VERSION ""

NS_ :

BS_:

BU_: FSM DCM BMS PDM INV DIM LOGGER DEBUG

BO_ 100 BMS_HEARTBEAT : 1 BMS
	SG_ HEARTBEAT : 0|1@1+ (1,0) [0|1] "" FSM,DCM,PDM,INV,DIM,DEBUG

BO_ 101 BMS_CAN_FIFO_OVERFLOW : 8 BMS
	SG_ TX_OVERFLOW_COUNT : 0|32@1+ (1,0) [0|4294967295] "" DEBUG
	SG_ RX_OVERFLOW_COUNT : 32|32@1+ (1,0) [0|4294967295] "" DEBUG

BO_ 102 BMS_STARTUP : 1 BMS
	SG_ STARTUP : 0|1@1+ (1,0) [0|1] "" DEBUG

BO_ 103 BMS_WATCHDOG_TIMEOUT : 1 BMS
	SG_ TASK_NAME : 0|2@1+ (1,0) [0|3] "" DEBUG

BO_ 104 BMS_NON_CRITICAL_ERRORS : 3 BMS
	SG_ STACK_WATERMARK_ABOVE_THRESHOLD_TASK1HZ : 0|1@1+ (1,0) [0|1] "" DEBUG
	SG_ STACK_WATERMARK_ABOVE_THRESHOLD_TASK1KHZ : 1|1@1+ (1,0) [0|1] "" DEBUG
	SG_ STACK_WATERMARK_ABOVE_THRESHOLD_TASKCANRX : 2|1@1+ (1,0) [0|1] "" DEBUG
	SG_ STACK_WATERMARK_ABOVE_THRESHOLD_TASKCANTX : 3|1@1+ (1,0) [0|1] "" DEBUG
	SG_ WATCHDOG_TIMEOUT : 4|1@1+ (1,0) [0|1] "" DEBUG
	SG_ SEGMENT_0_VOLTAGE_OUT_OF_RANGE : 5|1@1+ (1,0) [0|1] "" DEBUG
	SG_ SEGMENT_1_VOLTAGE_OUT_OF_RANGE : 6|1@1+ (1,0) [0|1] "" DEBUG
	SG_ SEGMENT_2_VOLTAGE_OUT_OF_RANGE : 7|1@1+ (1,0) [0|1] "" DEBUG
	SG_ SEGMENT_3_VOLTAGE_OUT_OF_RANGE : 8|1@1+ (1,0) [0|1] "" DEBUG
	SG_ SEGMENT_4_VOLTAGE_OUT_OF_RANGE : 9|1@1+ (1,0) [0|1] "" DEBUG
	SG_ SEGMENT_5_VOLTAGE_OUT_OF_RANGE : 10|1@1+ (1,0) [0|1] "" DEBUG
	SG_ PACK_VOLTAGE_OUT_OF_RANGE : 11|1@1+ (1,0) [0|1] "" DEBUG
	SG_ AVERAGE_CELL_VOLTAGE_OUT_OF_RANGE : 12|1@1+ (1,0) [0|1] "" DEBUG
	SG_ CELL_MONITOR_0_DIE_TEMP_OUT_OF_RANGE : 13|1@1+ (1,0) [0|1] "" DEBUG
	SG_ CELL_MONITOR_1_DIE_TEMP_OUT_OF_RANGE : 14|1@1+ (1,0) [0|1] "" DEBUG
	SG_ CELL_MONITOR_2_DIE_TEMP_OUT_OF_RANGE : 15|1@1+ (1,0) [0|1] "" DEBUG
	SG_ CELL_MONITOR_3_DIE_TEMP_OUT_OF_RANGE : 16|1@1+ (1,0) [0|1] "" DEBUG
	SG_ CELL_MONITOR_4_DIE_TEMP_OUT_OF_RANGE : 17|1@1+ (1,0) [0|1] "" DEBUG
	SG_ CELL_MONITOR_5_DIE_TEMP_OUT_OF_RANGE : 18|1@1+ (1,0) [0|1] "" DEBUG
	SG_ ITMP_CHARGER_HAS_OVERFLOW : 19|1@1+ (1,0) [0|1] "" DEBUG

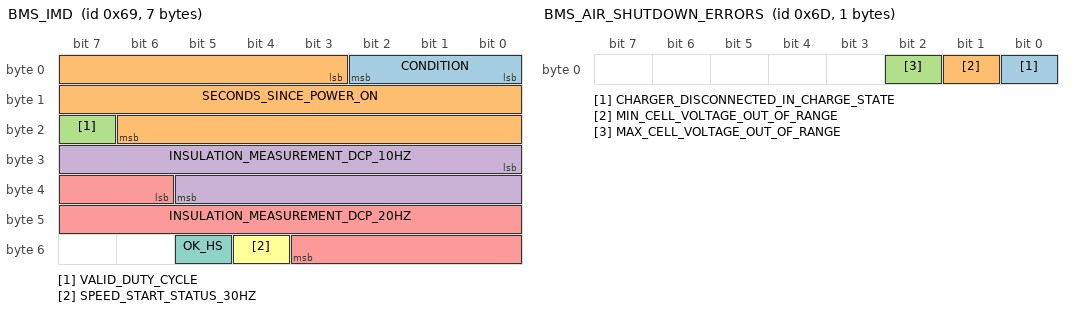
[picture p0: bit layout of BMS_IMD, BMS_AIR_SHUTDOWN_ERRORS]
BO_ 105 BMS_IMD : 7 BMS
	SG_ CONDITION : 0|3@1+ (1,0) [0|6] "" DEBUG
	SG_ SECONDS_SINCE_POWER_ON : 3|20@1+ (1,0) [0|604800] "seconds" DEBUG
	SG_ VALID_DUTY_CYCLE : 23|1@1+ (1,0) [0|1] "" DEBUG
	SG_ INSULATION_MEASUREMENT_DCP_10HZ : 24|14@1+ (1,0) [0|10000] "kOhms" DEBUG
	SG_ INSULATION_MEASUREMENT_DCP_20HZ : 38|14@1+ (1,0) [0|10000] "kOhms" DEBUG
	SG_ SPEED_START_STATUS_30HZ : 52|1@1+ (1,0) [0|1] "" DEBUG
	SG_ OK_HS : 53|1@1+ (1,0) [0|1] "" DIM,DEBUG

BO_ 106 BMS_IMD_PWM_OUTPUT : 4 BMS
	SG_ DUTY_CYCLE : 0|10@1+ (0.09775171065493646,0) [0|100] "%" DEBUG
	SG_ FREQUENCY : 10|19@1+ (0.0953676135399123,0) [0|50000] "Hz" DEBUG

BO_ 107 BMS_STATE_MACHINE : 1 BMS
	SG_ STATE : 0|3@1+ (1,0) [0|5] "" DEBUG

BO_ 108 BMS_STATE_OF_CHARGE : 2 BMS
	SG_ STATE_OF_CHARGE : 0|10@1+ (0.09775171065493646,0) [0|100] "%" DIM,DEBUG

BO_ 109 BMS_AIR_SHUTDOWN_ERRORS : 1 BMS
	SG_ CHARGER_DISCONNECTED_IN_CHARGE_STATE : 0|1@1+ (1,0) [0|1] "" DEBUG
	SG_ MIN_CELL_VOLTAGE_OUT_OF_RANGE : 1|1@1+ (1,0) [0|1] "" DEBUG
	SG_ MAX_CELL_VOLTAGE_OUT_OF_RANGE : 2|1@1+ (1,0) [0|1] "" DEBUG

BO_ 110 BMS_CHARGER : 1 BMS
	SG_ IS_CONNECTED : 0|1@1+ (1,0) [0|1] "" DEBUG

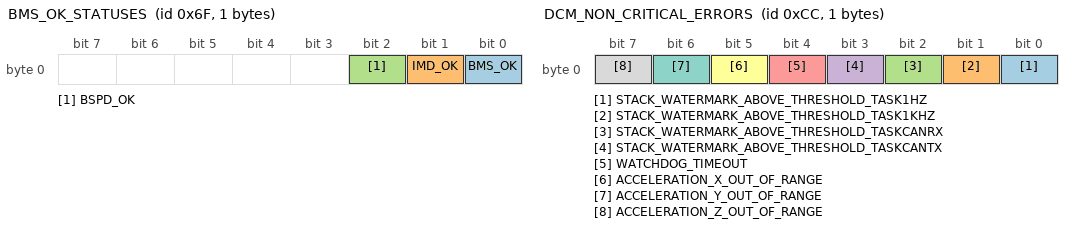
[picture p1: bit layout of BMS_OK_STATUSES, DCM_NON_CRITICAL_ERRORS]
BO_ 111 BMS_OK_STATUSES : 1 BMS
	SG_ BMS_OK : 0|1@1+ (1,0) [0|1] "" DEBUG
	SG_ IMD_OK : 1|1@1+ (1,0) [0|1] "" DEBUG
	SG_ BSPD_OK : 2|1@1+ (1,0) [0|1] "" DEBUG

BO_ 112 BMS_AIR_STATES : 1 BMS
	SG_ AIR_POSITIVE : 0|1@1+ (1,0) [0|1] "" FSM,DCM,PDM,DEBUG
	SG_ AIR_NEGATIVE : 1|1@1+ (1,0) [0|1] "" FSM,DCM,PDM,DEBUG

BO_ 113 BMS_MOTOR_SHUTDOWN_ERRORS : 1 BMS
	SG_ DUMMY_MOTOR_SHUTDOWN : 0|1@1+ (1,0) [0|1] "" DEBUG

BO_ 114 BMS_ACCUMULATOR_MIN_AND_MAX_VOLTAGES : 2 BMS
	SG_ MIN_CELL_VOLTAGE : 0|6@1+ (0.07936507936507936,0) [0|5] "V" DEBUG
	SG_ MAX_CELL_VOLTAGE : 6|6@1+ (0.07936507936507936,0) [0|5] "V" DEBUG

BO_ 115 BMS_ACCUMULATOR_PACK : 2 BMS
	SG_ PACK_VOLTAGE : 0|13@1+ (0.07935539006226346,0) [0|650] "V" DEBUG

BO_ 116 BMS_ACCUMULATOR_AVERAGE_CELL : 1 BMS
	SG_ AVERAGE_CELL_VOLTAGE : 0|6@1+ (0.07936507936507936,0) [0|5] "V" DEBUG

BO_ 117 BMS_ACCUMULATOR_SEGMENT_0 : 2 BMS
	SG_ SEGMENT_0_VOLTAGE : 0|11@1+ (0.07327796775769418,0) [0|150] "V" DEBUG

BO_ 118 BMS_ACCUMULATOR_SEGMENT_1 : 2 BMS
	SG_ SEGMENT_1_VOLTAGE : 0|11@1+ (0.07327796775769418,0) [0|150] "V" DEBUG

BO_ 119 BMS_ACCUMULATOR_SEGMENT_2 : 2 BMS
	SG_ SEGMENT_2_VOLTAGE : 0|11@1+ (0.07327796775769418,0) [0|150] "V" DEBUG

BO_ 120 BMS_ACCUMULATOR_SEGMENT_3 : 2 BMS
	SG_ SEGMENT_3_VOLTAGE : 0|11@1+ (0.07327796775769418,0) [0|150] "V" DEBUG

BO_ 121 BMS_ACCUMULATOR_SEGMENT_4 : 2 BMS
	SG_ SEGMENT_4_VOLTAGE : 0|11@1+ (0.07327796775769418,0) [0|150] "V" DEBUG

BO_ 122 BMS_ACCUMULATOR_SEGMENT_5 : 2 BMS
	SG_ SEGMENT_5_VOLTAGE : 0|11@1+ (0.07327796775769418,0) [0|150] "V" DEBUG

BO_ 123 BMS_CELL_MONITOR_0 : 2 BMS
	SG_ CELL_MONITOR_0_DIE_TEMPERATURE : 0|16@1- (0.004577776421399579,0) [-40|150] "degC" DEBUG

BO_ 124 BMS_CELL_MONITOR_1 : 1 BMS
	SG_ CELL_MONITOR_1_DIE_TEMPERATURE : 0|1@1- (1,0) [-40|150] "degC" DEBUG

BO_ 125 BMS_CELL_MONITOR_2 : 2 BMS
	SG_ CELL_MONITOR_2_DIE_TEMPERATURE : 0|9@1- (1,0) [-40|150] "degC" DEBUG

BO_ 126 BMS_CELL_MONITOR_3 : 2 BMS
	SG_ CELL_MONITOR_3_DIE_TEMPERATURE : 0|9@1- (1,0) [-40|150] "degC" DEBUG

BO_ 127 BMS_CELL_MONITOR_4 : 2 BMS
	SG_ CELL_MONITOR_4_DIE_TEMPERATURE : 0|9@1- (1,0) [-40|150] "degC" DEBUG

BO_ 128 BMS_CELL_MONITOR_5 : 2 BMS
	SG_ CELL_MONITOR_5_DIE_TEMPERATURE : 0|9@1- (1,0) [-40|150] "degC" DEBUG

BO_ 129 BMS_MAX_CELL_MONITOR : 2 BMS
	SG_ MAX_CELL_MONITOR_DIE_TEMPERATURE : 0|9@1- (1,0) [-40|150] "degC" DEBUG

BO_ 200 DCM_HEARTBEAT : 1 DCM
	SG_ HEARTBEAT : 0|1@1+ (1,0) [0|1] "" BMS,DEBUG

BO_ 201 DCM_CAN_FIFO_OVERFLOW : 8 DCM
	SG_ TX_OVERFLOW_COUNT : 0|32@1+ (1,0) [0|4294967295] "" DEBUG
	SG_ RX_OVERFLOW_COUNT : 32|32@1+ (1,0) [0|4294967295] "" DEBUG

BO_ 202 DCM_STARTUP : 1 DCM
	SG_ STARTUP : 0|1@1+ (1,0) [0|1] "" DEBUG

BO_ 203 DCM_WATCHDOG_TIMEOUT : 1 DCM
	SG_ TASK_NAME : 0|3@1+ (1,0) [0|5] "" DEBUG

BO_ 204 DCM_NON_CRITICAL_ERRORS : 1 DCM
	SG_ STACK_WATERMARK_ABOVE_THRESHOLD_TASK1HZ : 0|1@1+ (1,0) [0|1] "" DEBUG
	SG_ STACK_WATERMARK_ABOVE_THRESHOLD_TASK1KHZ : 1|1@1+ (1,0) [0|1] "" DEBUG
	SG_ STACK_WATERMARK_ABOVE_THRESHOLD_TASKCANRX : 2|1@1+ (1,0) [0|1] "" DEBUG
	SG_ STACK_WATERMARK_ABOVE_THRESHOLD_TASKCANTX : 3|1@1+ (1,0) [0|1] "" DEBUG
	SG_ WATCHDOG_TIMEOUT : 4|1@1+ (1,0) [0|1] "" DEBUG
	SG_ ACCELERATION_X_OUT_OF_RANGE : 5|1@1+ (1,0) [0|1] "" DEBUG
	SG_ ACCELERATION_Y_OUT_OF_RANGE : 6|1@1+ (1,0) [0|1] "" DEBUG
	SG_ ACCELERATION_Z_OUT_OF_RANGE : 7|1@1+ (1,0) [0|1] "" DEBUG

BO_ 205 DCM_STATE_MACHINE : 1 DCM
	SG_ STATE : 0|2@1+ (1,0) [0|2] "" DEBUG

BO_ 206 DCM_TORQUE_REQUEST_FRONT : 8 DCM
	SG_ FR_TORQUE_REQUEST : 0|32@1- (1,0) [-90|90] "Nm" INV,LOGGER,DEBUG
	SG_ FL_TORQUE_REQUEST : 32|32@1- (1,0) [-90|90] "Nm" INV,LOGGER,DEBUG

BO_ 207 DCM_TORQUE_REQUEST_REAR : 8 DCM
	SG_ RR_TORQUE_REQUEST : 0|32@1- (1,0) [-90|90] "Nm" INV,LOGGER,DEBUG
	SG_ RL_TORQUE_REQUEST : 32|32@1- (1,0) [-90|90] "Nm" INV,LOGGER,DEBUG

BO_ 208 DCM_AIR_SHUTDOWN_ERRORS : 1 DCM
	SG_ DUMMY_AIR_SHUTDOWN : 0|1@1+ (1,0) [0|1] "" DEBUG

BO_ 209 DCM_MOTOR_SHUTDOWN_ERRORS : 1 DCM
	SG_ DUMMY_MOTOR_SHUTDOWN : 0|1@1+ (1,0) [0|1] "" DEBUG

BO_ 210 DCM_ACCELERATION_X : 2 DCM
	SG_ ACCELERATION_X : 0|10@1+ (0.09775171065493646,0) [0|100] "m/s^2" DEBUG

BO_ 211 DCM_ACCELERATION_Y : 2 DCM
	SG_ ACCELERATION_Y : 0|10@1+ (0.09775171065493646,0) [0|100] "m/s^2" DEBUG

BO_ 212 DCM_ACCELERATION_Z : 2 DCM
	SG_ ACCELERATION_Z : 0|10@1+ (0.09775171065493646,0) [0|100] "m/s^2" DEBUG

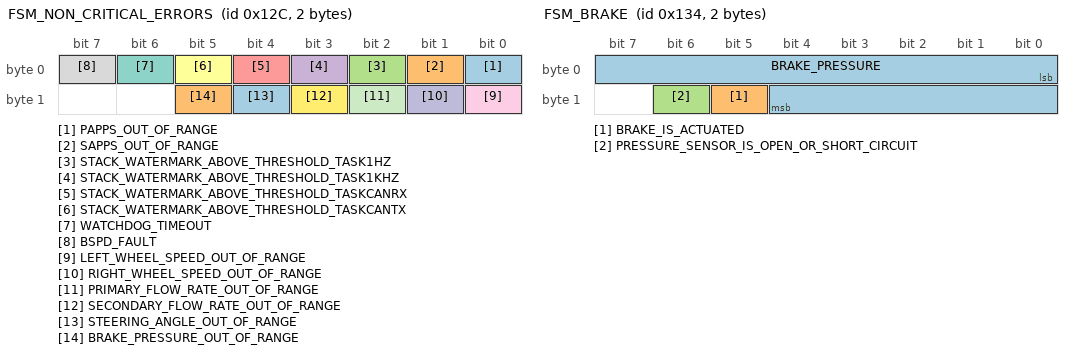
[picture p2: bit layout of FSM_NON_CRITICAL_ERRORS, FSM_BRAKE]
BO_ 300 FSM_NON_CRITICAL_ERRORS : 2 FSM
	SG_ PAPPS_OUT_OF_RANGE : 0|1@1+ (1,0) [0|1] "" DEBUG
	SG_ SAPPS_OUT_OF_RANGE : 1|1@1+ (1,0) [0|1] "" DEBUG
	SG_ STACK_WATERMARK_ABOVE_THRESHOLD_TASK1HZ : 2|1@1+ (1,0) [0|1] "" DEBUG
	SG_ STACK_WATERMARK_ABOVE_THRESHOLD_TASK1KHZ : 3|1@1+ (1,0) [0|1] "" DEBUG
	SG_ STACK_WATERMARK_ABOVE_THRESHOLD_TASKCANRX : 4|1@1+ (1,0) [0|1] "" DEBUG
	SG_ STACK_WATERMARK_ABOVE_THRESHOLD_TASKCANTX : 5|1@1+ (1,0) [0|1] "" DEBUG
	SG_ WATCHDOG_TIMEOUT : 6|1@1+ (1,0) [0|1] "" DEBUG
	SG_ BSPD_FAULT : 7|1@1+ (1,0) [0|1] "" DIM,DEBUG
	SG_ LEFT_WHEEL_SPEED_OUT_OF_RANGE : 8|1@1+ (1,0) [0|1] "" DEBUG
	SG_ RIGHT_WHEEL_SPEED_OUT_OF_RANGE : 9|1@1+ (1,0) [0|1] "" DEBUG
	SG_ PRIMARY_FLOW_RATE_OUT_OF_RANGE : 10|1@1+ (1,0) [0|1] "" DEBUG
	SG_ SECONDARY_FLOW_RATE_OUT_OF_RANGE : 11|1@1+ (1,0) [0|1] "" DEBUG
	SG_ STEERING_ANGLE_OUT_OF_RANGE : 12|1@1+ (1,0) [0|1] "" DEBUG
	SG_ BRAKE_PRESSURE_OUT_OF_RANGE : 13|1@1+ (1,0) [0|1] "" DEBUG

BO_ 301 FSM_HEARTBEAT : 1 FSM
	SG_ HEARTBEAT : 0|1@1+ (1,0) [0|1] "" BMS,DEBUG

BO_ 302 FSM_CAN_FIFO_OVERFLOW : 8 FSM
	SG_ TX_OVERFLOW_COUNT : 0|32@1+ (1,0) [0|4294967295] "" DEBUG
	SG_ RX_OVERFLOW_COUNT : 32|32@1+ (1,0) [0|4294967295] "" DEBUG

BO_ 303 FSM_STARTUP : 1 FSM
	SG_ STARTUP : 0|1@1+ (1,0) [0|1] "" DEBUG

BO_ 304 FSM_WATCHDOG_TIMEOUT : 1 FSM
	SG_ TASK_NAME : 0|3@1+ (1,0) [0|5] "" DEBUG

BO_ 305 FSM_STATE_MACHINE : 1 FSM
	SG_ STATE : 0|1@1+ (1,0) [0|1] "" DEBUG

BO_ 306 FSM_AIR_SHUTDOWN : 1 FSM
	SG_ AIR_SHUTDOWN : 0|1@1+ (1,0) [0|1] "" DEBUG

BO_ 307 FSM_FLOW_METER : 3 FSM
	SG_ PRIMARY_FLOW_RATE : 0|9@1+ (0.04892367906066536,0) [0|25] "L/min" DEBUG
	SG_ SECONDARY_FLOW_RATE : 9|9@1+ (0.04892367906066536,0) [0|25] "L/min" DEBUG

BO_ 308 FSM_BRAKE : 2 FSM
	SG_ BRAKE_PRESSURE : 0|13@1+ (0.06104260774020266,0) [0|500] "psi" DEBUG
	SG_ BRAKE_IS_ACTUATED : 13|1@1+ (1,0) [0|1] "" DCM,DEBUG
	SG_ PRESSURE_SENSOR_IS_OPEN_OR_SHORT_CIRCUIT : 14|1@1+ (1,0) [0|1] "" DEBUG

BO_ 309 FSM_WHEEL_SPEED_SENSOR : 3 FSM
	SG_ LEFT_WHEEL_SPEED : 0|10@1+ (0.09775171065493646,0) [0|100] "km/h" DCM,DEBUG
	SG_ RIGHT_WHEEL_SPEED : 10|10@1+ (0.09775171065493646,0) [0|100] "km/h" DCM,DEBUG

BO_ 310 FSM_AIR_SHUTDOWN_ERRORS : 1 FSM
	SG_ DUMMY_AIR_SHUTDOWN : 0|1@1+ (1,0) [0|1] "" DEBUG

BO_ 311 FSM_STEERING_ANGLE_SENSOR : 2 FSM
	SG_ STEERING_ANGLE : 0|13@1- (0.04395604395604396,0) [-180|180] "degrees" DCM,DEBUG

BO_ 312 FSM_PRIMARY_APPS : 2 FSM
	SG_ PAPPS_MAPPED_PEDAL_PERCENTAGE : 0|10@1+ (0.09775171065493646,0) [0|100] "%" DEBUG

BO_ 313 FSM_SECONDARY_APPS : 2 FSM
	SG_ SAPPS_MAPPED_PEDAL_PERCENTAGE : 0|10@1+ (0.09775171065493646,0) [0|100] "%" DEBUG

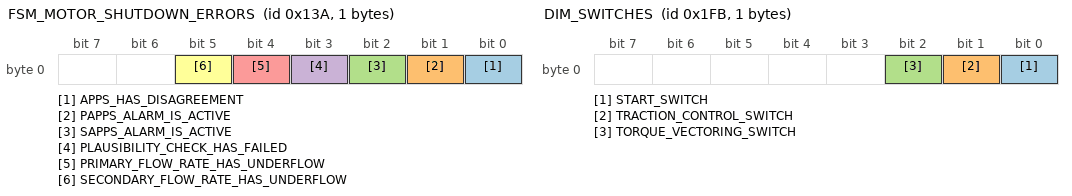
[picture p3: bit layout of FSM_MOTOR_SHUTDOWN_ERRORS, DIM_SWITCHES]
BO_ 314 FSM_MOTOR_SHUTDOWN_ERRORS : 1 FSM
	SG_ APPS_HAS_DISAGREEMENT : 0|1@1+ (1,0) [0|1] "" DEBUG
	SG_ PAPPS_ALARM_IS_ACTIVE : 1|1@1+ (1,0) [0|1] "" DEBUG
	SG_ SAPPS_ALARM_IS_ACTIVE : 2|1@1+ (1,0) [0|1] "" DEBUG
	SG_ PLAUSIBILITY_CHECK_HAS_FAILED : 3|1@1+ (1,0) [0|1] "" DEBUG
	SG_ PRIMARY_FLOW_RATE_HAS_UNDERFLOW : 4|1@1+ (1,0) [0|1] "" DEBUG
	SG_ SECONDARY_FLOW_RATE_HAS_UNDERFLOW : 5|1@1+ (1,0) [0|1] "" DEBUG

BO_ 315 FSM_PEDAL_POSITION : 2 FSM
	SG_ MAPPED_PEDAL_PERCENTAGE : 0|10@1+ (0.09775171065493646,0) [0|100] "%" DCM,DEBUG

BO_ 400 PDM_NON_CRITICAL_ERRORS : 3 PDM
	SG_ MISSING_HEARTBEAT : 0|1@1+ (1,0) [0|1] "" DEBUG
	SG_ BOOST_PGOOD_FAULT : 1|1@1+ (1,0) [0|1] "" DEBUG
	SG_ CHARGER_FAULT : 2|1@1+ (1,0) [0|1] "" DEBUG
	SG_ EFUSE_FAULT : 3|1@1+ (1,0) [0|1] "" DEBUG
	SG_ STACK_WATERMARK_ABOVE_THRESHOLD_TASK1HZ : 4|1@1+ (1,0) [0|1] "" DEBUG
	SG_ STACK_WATERMARK_ABOVE_THRESHOLD_TASK1KHZ : 5|1@1+ (1,0) [0|1] "" DEBUG
	SG_ STACK_WATERMARK_ABOVE_THRESHOLD_TASKCANRX : 6|1@1+ (1,0) [0|1] "" DEBUG
	SG_ STACK_WATERMARK_ABOVE_THRESHOLD_TASKCANTX : 7|1@1+ (1,0) [0|1] "" DEBUG
	SG_ WATCHDOG_TIMEOUT : 8|1@1+ (1,0) [0|1] "" DEBUG
	SG_ VBAT_VOLTAGE_OUT_OF_RANGE : 9|1@1+ (1,0) [0|1] "" DEBUG
	SG_ _24V_AUX_VOLTAGE_OUT_OF_RANGE : 10|1@1+ (1,0) [0|1] "" DEBUG
	SG_ _24V_ACC_VOLTAGE_OUT_OF_RANGE : 11|1@1+ (1,0) [0|1] "" DEBUG
	SG_ AUX1_CURRENT_OUT_OF_RANGE : 12|1@1+ (1,0) [0|1] "" DEBUG
	SG_ AUX2_CURRENT_OUT_OF_RANGE : 13|1@1+ (1,0) [0|1] "" DEBUG
	SG_ LEFT_INVERTER_CURRENT_OUT_OF_RANGE : 14|1@1+ (1,0) [0|1] "" DEBUG
	SG_ RIGHT_INVERTER_CURRENT_OUT_OF_RANGE : 15|1@1+ (1,0) [0|1] "" DEBUG
	SG_ ENERGY_METER_CURRENT_OUT_OF_RANGE : 16|1@1+ (1,0) [0|1] "" DEBUG
	SG_ CAN_CURRENT_OUT_OF_RANGE : 17|1@1+ (1,0) [0|1] "" DEBUG
	SG_ AIR_SHUTDOWN_CURRENT_OUT_OF_RANGE : 18|1@1+ (1,0) [0|1] "" DEBUG

BO_ 401 PDM_HEARTBEAT : 1 PDM
	SG_ HEARTBEAT : 0|1@1+ (1,0) [0|1] "" BMS,DEBUG

BO_ 402 PDM_CAN_FIFO_OVERFLOW : 8 PDM
	SG_ TX_OVERFLOW_COUNT : 0|32@1+ (1,0) [0|4294967295] "" DEBUG
	SG_ RX_OVERFLOW_COUNT : 32|32@1+ (1,0) [0|4294967295] "" DEBUG

BO_ 403 PDM_STARTUP : 1 PDM
	SG_ STARTUP : 0|1@1+ (1,0) [0|1] "" DEBUG

BO_ 404 PDM_AIR_SHUTDOWN_ERRORS : 1 PDM
	SG_ DUMMY_AIR_SHUTDOWN : 0|1@1+ (1,0) [0|1] "" DEBUG

BO_ 405 PDM_MOTOR_SHUTDOWN_ERRORS : 1 PDM
	SG_ DUMMY_MOTOR_SHUTDOWN : 0|1@1+ (1,0) [0|1] "" DEBUG

BO_ 406 PDM_AUX1_AUX2_CURRENT : 4 PDM
	SG_ AUXILIARY1_CURRENT : 0|16@1+ (0.07629510948348212,0) [0|5000] "mA" DEBUG
	SG_ AUXILIARY2_CURRENT : 16|16@1+ (0.07629510948348212,0) [0|5000] "mA" DEBUG

BO_ 407 PDM_ENERGY_METER_CURRENT : 4 PDM
	SG_ ENERGY_METER_CURRENT : 0|16@1+ (0.07629510948348212,0) [0|5000] "mA" DEBUG
	SG_ UNUSED : 16|16@1+ (0.07629510948348212,0) [0|5000] "mA" DEBUG

BO_ 408 PDM_AIRSHDN_CANGLV_CURRENT : 4 PDM
	SG_ CAN_CURRENT : 0|16@1+ (0.07629510948348212,0) [0|5000] "mA" DEBUG
	SG_ AIR_SHUTDOWN_CURRENT : 16|16@1+ (0.1,0) [0|5000] "mA" DEBUG

BO_ 409 PDM_INVERTER_CURRENT : 4 PDM
	SG_ LEFT_INVERTER_CURRENT : 0|16@1+ (0.1,0) [0|5000] "mA" DEBUG
	SG_ RIGHT_INVERTER_CURRENT : 16|16@1+ (0.1,0) [0|5000] "mA" DEBUG

BO_ 410 PDM_24V : 3 PDM
	SG_ _24V_AUX : 0|9@1+ (0.1,0) [0|30] "V" DEBUG
	SG_ _24V_ACC : 9|9@1+ (0.1,0) [0|30] "V" DEBUG

BO_ 411 PDM_VBAT : 1 PDM
	SG_ VBAT : 0|7@1+ (0.1,0) [0|10] "V" DEBUG

BO_ 412 PDM_WATCHDOG_TIMEOUT : 1 PDM
	SG_ TASK_NAME : 0|3@1+ (1,0) [0|5] "" DEBUG

BO_ 413 PDM_STATE_MACHINE : 1 PDM
	SG_ STATE : 0|2@1+ (1,0) [0|2] "" DEBUG

BO_ 500 DIM_HEARTBEAT : 1 DIM
	SG_ HEARTBEAT : 0|1@1+ (1,0) [0|1] "" FSM,DCM,BMS,PDM,DEBUG

BO_ 501 DIM_CAN_FIFO_OVERFLOW : 8 DIM
	SG_ TX_OVERFLOW_COUNT : 0|32@1+ (1,0) [0|4294967295] "" DEBUG
	SG_ RX_OVERFLOW_COUNT : 32|32@1+ (1,0) [0|4294967295] "" DEBUG

BO_ 502 DIM_STARTUP : 1 DIM
	SG_ STARTUP : 0|1@1+ (1,0) [0|1] "" DEBUG

BO_ 503 DIM_STATE_MACHINE : 1 DIM
	SG_ STATE : 0|1@1+ (1,0) [0|1] "" DEBUG

BO_ 504 DIM_WATCHDOG_TIMEOUT : 1 DIM
	SG_ TASK_NAME : 0|3@1+ (1,0) [0|5] "" DEBUG

BO_ 505 DIM_REGEN_PADDLE : 2 DIM
	SG_ RAW_PADDLE_POSITION : 0|6@1+ (0.1,0) [0|3.5] "V" DEBUG
	SG_ MAPPED_PADDLE_POSITION : 6|10@1+ (0.1,0) [0|100] "%" DCM,DEBUG

BO_ 506 DIM_DRIVE_MODE_SWITCH : 1 DIM
	SG_ DRIVE_MODE : 0|3@1+ (1,0) [0|5] "" DCM,DEBUG

BO_ 507 DIM_SWITCHES : 1 DIM
	SG_ START_SWITCH : 0|1@1+ (1,0) [0|1] "" DCM,DEBUG
	SG_ TRACTION_CONTROL_SWITCH : 1|1@1+ (1,0) [0|1] "" DCM,DEBUG
	SG_ TORQUE_VECTORING_SWITCH : 2|1@1+ (1,0) [0|1] "" DCM,DEBUG

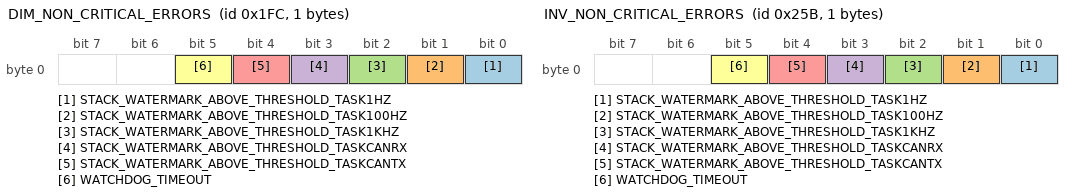
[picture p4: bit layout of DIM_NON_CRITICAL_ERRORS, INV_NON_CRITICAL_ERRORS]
BO_ 508 DIM_NON_CRITICAL_ERRORS : 1 DIM
	SG_ STACK_WATERMARK_ABOVE_THRESHOLD_TASK1HZ : 0|1@1+ (1,0) [0|1] "" DEBUG
	SG_ STACK_WATERMARK_ABOVE_THRESHOLD_TASK100HZ : 1|1@1+ (1,0) [0|1] "" DEBUG
	SG_ STACK_WATERMARK_ABOVE_THRESHOLD_TASK1KHZ : 2|1@1+ (1,0) [0|1] "" DEBUG
	SG_ STACK_WATERMARK_ABOVE_THRESHOLD_TASKCANRX : 3|1@1+ (1,0) [0|1] "" DEBUG
	SG_ STACK_WATERMARK_ABOVE_THRESHOLD_TASKCANTX : 4|1@1+ (1,0) [0|1] "" DEBUG
	SG_ WATCHDOG_TIMEOUT : 5|1@1+ (1,0) [0|1] "" DEBUG

BO_ 509 DIM_AIR_SHUTDOWN_ERRORS : 1 DIM
	SG_ DUMMY_AIR_SHUTDOWN : 0|1@1+ (1,0) [0|1] "" DEBUG

BO_ 510 DIM_MOTOR_SHUTDOWN_ERRORS : 1 DIM
	SG_ DUMMY_MOTOR_SHUTDOWN : 0|1@1+ (1,0) [0|1] "" DEBUG

BO_ 600 INV_HEARTBEAT : 1 INV
	SG_ HEARTBEAT : 0|1@1+ (1,0) [0|1] "" FSM,DCM,BMS,PDM,DIM,DEBUG

BO_ 601 INV_CAN_FIFO_OVERFLOW : 8 INV
	SG_ TX_OVERFLOW_COUNT : 0|32@1+ (1,0) [0|4294967295] "" DEBUG
	SG_ RX_OVERFLOW_COUNT : 32|32@1+ (1,0) [0|4294967295] "" DEBUG

BO_ 602 INV_WATCHDOG_TIMEOUT : 1 INV
	SG_ TASK_NAME : 0|3@1+ (1,0) [0|5] "" DEBUG

BO_ 603 INV_NON_CRITICAL_ERRORS : 1 INV
	SG_ STACK_WATERMARK_ABOVE_THRESHOLD_TASK1HZ : 0|1@1+ (1,0) [0|1] "" LOGGER,DEBUG
	SG_ STACK_WATERMARK_ABOVE_THRESHOLD_TASK100HZ : 1|1@1+ (1,0) [0|1] "" LOGGER,DEBUG
	SG_ STACK_WATERMARK_ABOVE_THRESHOLD_TASK1KHZ : 2|1@1+ (1,0) [0|1] "" LOGGER,DEBUG
	SG_ STACK_WATERMARK_ABOVE_THRESHOLD_TASKCANRX : 3|1@1+ (1,0) [0|1] "" LOGGER,DEBUG
	SG_ STACK_WATERMARK_ABOVE_THRESHOLD_TASKCANTX : 4|1@1+ (1,0) [0|1] "" LOGGER,DEBUG
	SG_ WATCHDOG_TIMEOUT : 5|1@1+ (1,0) [0|1] "" LOGGER,DEBUG

BO_ 604 INV_AIR_SHUTDOWN_ERRORS : 1 INV
	SG_ DUMMY_AIR_SHUTDOWN : 0|1@1+ (1,0) [0|1] "" DEBUG

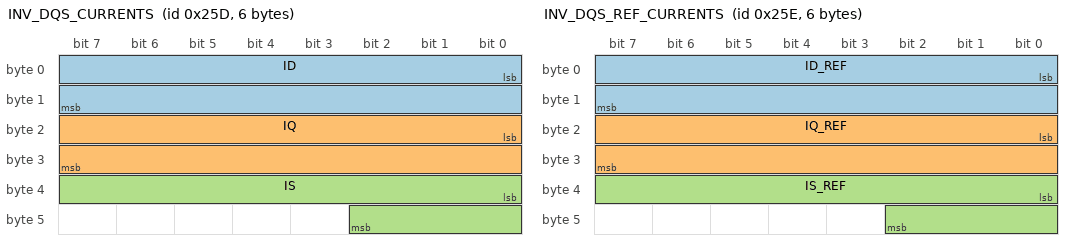
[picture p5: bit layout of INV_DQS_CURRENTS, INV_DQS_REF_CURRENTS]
BO_ 605 INV_DQS_CURRENTS : 6 INV
	SG_ ID : 0|16@1- (0.1,0) [-3276.8|3276.7] "A" DEBUG
	SG_ IQ : 16|16@1- (0.1,0) [-3276.8|3276.7] "A" DEBUG
	SG_ IS : 32|11@1+ (0.1,0) [0|200] "A" DEBUG

BO_ 606 INV_DQS_REF_CURRENTS : 6 INV
	SG_ ID_REF : 0|16@1- (0.1,0) [-3276.8|3276.7] "A" DEBUG
	SG_ IQ_REF : 16|16@1- (0.1,0) [-3276.8|3276.7] "A" DEBUG
	SG_ IS_REF : 32|11@1+ (0.1,0) [0|200] "A" DEBUG

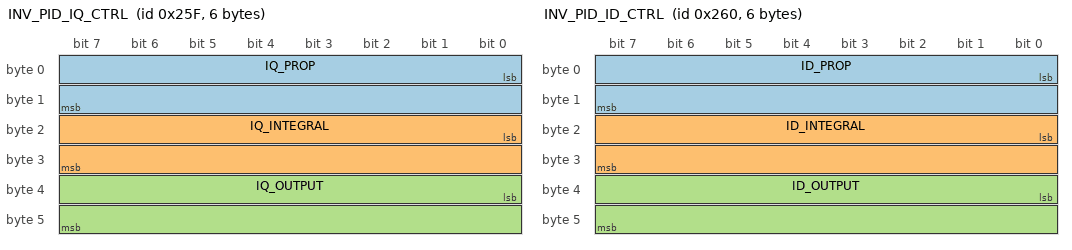
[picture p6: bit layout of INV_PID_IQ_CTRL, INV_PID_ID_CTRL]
BO_ 607 INV_PID_IQ_CTRL : 6 INV
	SG_ IQ_PROP : 0|16@1- (0.1,0) [-3276.8|3276.7] "V" DEBUG
	SG_ IQ_INTEGRAL : 16|16@1- (0.1,0) [-3276.8|3276.7] "V" DEBUG
	SG_ IQ_OUTPUT : 32|16@1- (0.1,0) [-3276.8|3276.7] "V" DEBUG

BO_ 608 INV_PID_ID_CTRL : 6 INV
	SG_ ID_PROP : 0|16@1- (0.1,0) [-3276.8|3276.7] "V" DEBUG
	SG_ ID_INTEGRAL : 16|16@1- (0.1,0) [-3276.8|3276.7] "V" DEBUG
	SG_ ID_OUTPUT : 32|16@1- (0.1,0) [-3276.8|3276.7] "V" DEBUG

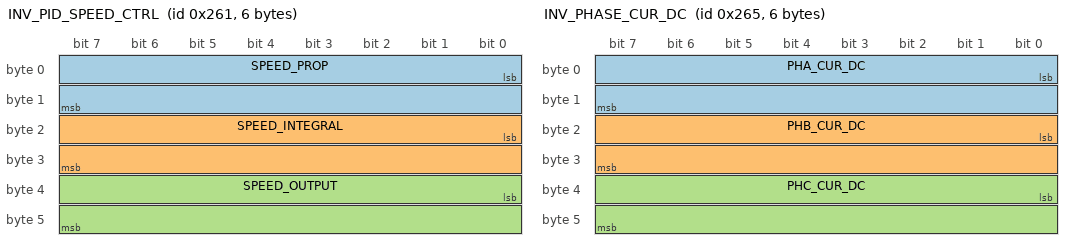
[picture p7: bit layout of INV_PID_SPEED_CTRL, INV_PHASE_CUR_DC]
BO_ 609 INV_PID_SPEED_CTRL : 6 INV
	SG_ SPEED_PROP : 0|16@1- (0.1,0) [-3276.8|3276.7] "Nm" DEBUG
	SG_ SPEED_INTEGRAL : 16|16@1- (0.1,0) [-3276.8|3276.7] "Nm" DEBUG
	SG_ SPEED_OUTPUT : 32|16@1- (0.1,0) [-3276.8|3276.7] "Nm" DEBUG

BO_ 610 INV_VPHASE_LN : 2 INV
	SG_ VPHASE_LN : 0|13@1+ (0.1,0) [0|500] "V" DEBUG

BO_ 611 INV_MOD_INDEX : 2 INV
	SG_ MOD_INDEX : 0|10@1+ (0.1,0) [0|100] "%" DEBUG

BO_ 612 INV_BUS_VOLTAGE : 2 INV
	SG_ BUS_VOLTAGE : 0|13@1+ (0.1,0) [0|800] "V" DEBUG

BO_ 613 INV_PHASE_CUR_DC : 6 INV
	SG_ PHA_CUR_DC : 0|16@1- (0.09999999999999999,0) [-3276.8|3276.7] "A" DEBUG
	SG_ PHB_CUR_DC : 16|16@1- (0.09999999999999999,0) [-3276.8|3276.7] "A" DEBUG
	SG_ PHC_CUR_DC : 32|16@1- (0.09999999999999999,0) [-3276.8|3276.7] "A" DEBUG

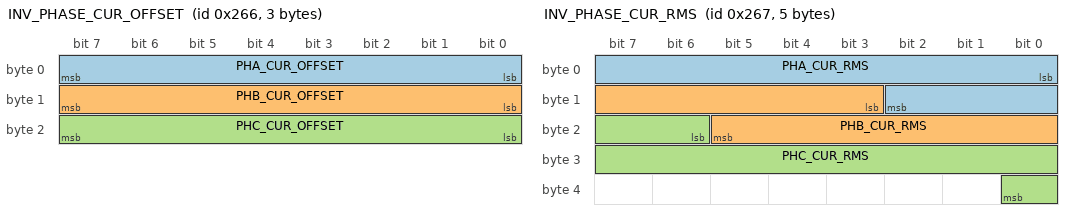
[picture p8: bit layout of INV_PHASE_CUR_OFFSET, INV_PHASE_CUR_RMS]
BO_ 614 INV_PHASE_CUR_OFFSET : 3 INV
	SG_ PHA_CUR_OFFSET : 0|8@1- (1,0) [-128|127] "A" DEBUG
	SG_ PHB_CUR_OFFSET : 8|8@1- (1,0) [-128|127] "A" DEBUG
	SG_ PHC_CUR_OFFSET : 16|8@1- (1,0) [-128|127] "A" DEBUG

BO_ 615 INV_PHASE_CUR_RMS : 5 INV
	SG_ PHA_CUR_RMS : 0|11@1+ (0.1,0) [0|200] "Arms" DEBUG
	SG_ PHB_CUR_RMS : 11|11@1+ (0.1,0) [0|200] "Arms" DEBUG
	SG_ PHC_CUR_RMS : 22|11@1+ (0.1,0) [0|200] "Arms" DEBUG

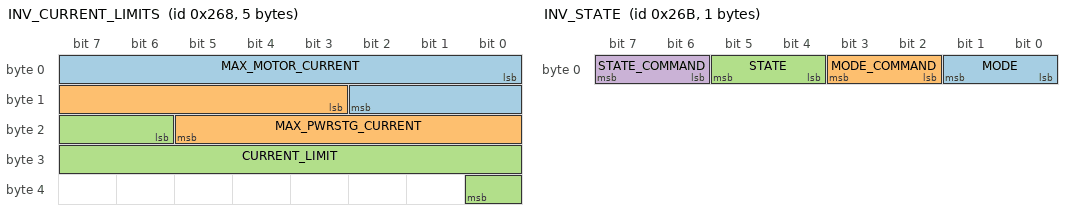
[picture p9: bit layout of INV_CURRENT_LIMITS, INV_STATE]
BO_ 616 INV_CURRENT_LIMITS : 5 INV
	SG_ MAX_MOTOR_CURRENT : 0|11@1+ (0.1,0) [0|150] "A" DEBUG
	SG_ MAX_PWRSTG_CURRENT : 11|11@1+ (0.1,0) [0|150] "A" DEBUG
	SG_ CURRENT_LIMIT : 22|11@1+ (0.1,0) [0|150] "A" DEBUG

BO_ 617 INV_TEMPS : 4 INV
	SG_ PWRSTG_TEMP : 0|16@1- (0.1,0) [-3276.8|3276.7] "degC" DEBUG
	SG_ MOTOR_TEMP : 16|16@1- (0.1,0) [-3276.8|3276.7] "degC" DEBUG

BO_ 618 INV_ROTOR : 4 INV
	SG_ ROTOR_POSITION : 0|12@1+ (0.1,0) [0|400] "degrees" DEBUG
	SG_ ROTOR_SPEED : 12|16@1- (1,0) [-32768|32767] "rpm" DEBUG

BO_ 619 INV_STATE : 1 INV
	SG_ MODE : 0|2@1+ (1,0) [0|3] "" DEBUG
	SG_ MODE_COMMAND : 2|2@1+ (1,0) [0|3] "" DEBUG
	SG_ STATE : 4|2@1+ (1,0) [0|3] "" DEBUG
	SG_ STATE_COMMAND : 6|2@1+ (1,0) [0|3] "" DEBUG

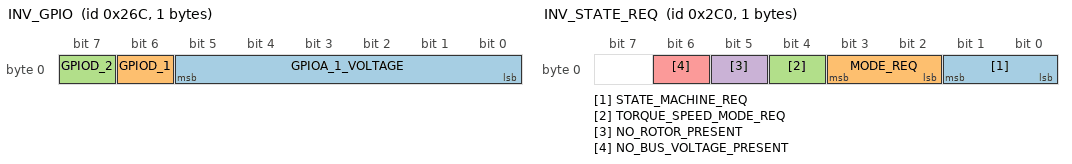
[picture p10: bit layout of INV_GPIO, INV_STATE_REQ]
BO_ 620 INV_GPIO : 1 INV
	SG_ GPIOA_1_VOLTAGE : 0|6@1+ (0.1,0) [0|3.5] "V" DEBUG
	SG_ GPIOD_1 : 6|1@1+ (1,0) [0|1] "" DEBUG
	SG_ GPIOD_2 : 7|1@1+ (1,0) [0|1] "" DEBUG

BO_ 621 INV_DAC_OUT1 : 2 INV
	SG_ DAC_OUT1_VOLTAGE : 0|6@1+ (0.1,0) [0|3.5] "V" DEBUG
	SG_ DAC_OUT1_CURRENT_LIM : 6|8@1- (1,0) [-128|127] "A" DEBUG

BO_ 622 INV_DAC_OUT2 : 2 INV
	SG_ DAC_OUT2_VOLTAGE : 0|6@1+ (0.1,0) [0|3.5] "V" DEBUG
	SG_ DAC_OUT2_CURRENT_LIM : 6|8@1- (1,0) [-128|127] "A" DEBUG

BO_ 623 INV_PHA_STGAP_FAULTS : 4 INV
	SG_ A_LO_THERM_WARN : 0|1@1+ (1,0) [0|1] "" DEBUG
	SG_ A_LO_THERM_SHDN : 1|1@1+ (1,0) [0|1] "" DEBUG
	SG_ A_LO_UVLOL : 2|1@1+ (1,0) [0|1] "" DEBUG
	SG_ A_LO_UVLOH : 3|1@1+ (1,0) [0|1] "" DEBUG
	SG_ A_LO_SENSE : 4|1@1+ (1,0) [0|1] "" DEBUG
	SG_ A_LO_DESAT : 5|1@1+ (1,0) [0|1] "" DEBUG
	SG_ A_LO_OVLOL : 6|1@1+ (1,0) [0|1] "" DEBUG
	SG_ A_LO_OVLOH : 7|1@1+ (1,0) [0|1] "" DEBUG
	SG_ A_LO_ASC : 8|1@1+ (1,0) [0|1] "" DEBUG
	SG_ A_LO_REGERR_ISO : 9|1@1+ (1,0) [0|1] "" DEBUG
	SG_ A_LO_UVLOD : 10|1@1+ (1,0) [0|1] "" DEBUG
	SG_ A_LO_OVLOD : 11|1@1+ (1,0) [0|1] "" DEBUG
	SG_ A_LO_REGERR_LV : 12|1@1+ (1,0) [0|1] "" DEBUG
	SG_ A_LO_SPI_ERR : 13|1@1+ (1,0) [0|1] "" DEBUG
	SG_ A_LO_DEADTIME_ERR : 14|1@1+ (1,0) [0|1] "" DEBUG
	SG_ A_HI_THERM_WARN : 15|1@1+ (1,0) [0|1] "" DEBUG
	SG_ A_HI_THERM_SHDN : 16|1@1+ (1,0) [0|1] "" DEBUG
	SG_ A_HI_UVLOL : 17|1@1+ (1,0) [0|1] "" DEBUG
	SG_ A_HI_UVLOH : 18|1@1+ (1,0) [0|1] "" DEBUG
	SG_ A_HI_SENSE : 19|1@1+ (1,0) [0|1] "" DEBUG
	SG_ A_HI_DESAT : 20|1@1+ (1,0) [0|1] "" DEBUG
	SG_ A_HI_OVLOL : 21|1@1+ (1,0) [0|1] "" DEBUG
	SG_ A_HI_OVLOH : 22|1@1+ (1,0) [0|1] "" DEBUG
	SG_ A_HI_ASC : 23|1@1+ (1,0) [0|1] "" DEBUG
	SG_ A_HI_REGERR_ISO : 24|1@1+ (1,0) [0|1] "" DEBUG
	SG_ A_HI_UVLOD : 25|1@1+ (1,0) [0|1] "" DEBUG
	SG_ A_HI_OVLOD : 26|1@1+ (1,0) [0|1] "" DEBUG
	SG_ A_HI_REGERR_LV : 27|1@1+ (1,0) [0|1] "" DEBUG
	SG_ A_HI_SPI_ERR : 28|1@1+ (1,0) [0|1] "" DEBUG
	SG_ A_HI_DEADTIME_ERR : 29|1@1+ (1,0) [0|1] "" DEBUG

BO_ 624 INV_PHB_STGAP_FAULTS : 4 INV
	SG_ B_LO_THERM_WARN : 0|1@1+ (1,0) [0|1] "" DEBUG
	SG_ B_LO_THERM_SHDN : 1|1@1+ (1,0) [0|1] "" DEBUG
	SG_ B_LO_UVLOL : 2|1@1+ (1,0) [0|1] "" DEBUG
	SG_ B_LO_UVLOH : 3|1@1+ (1,0) [0|1] "" DEBUG
	SG_ B_LO_SENSE : 4|1@1+ (1,0) [0|1] "" DEBUG
	SG_ B_LO_DESAT : 5|1@1+ (1,0) [0|1] "" DEBUG
	SG_ B_LO_OVLOL : 6|1@1+ (1,0) [0|1] "" DEBUG
	SG_ B_LO_OVLOH : 7|1@1+ (1,0) [0|1] "" DEBUG
	SG_ B_LO_ASC : 8|1@1+ (1,0) [0|1] "" DEBUG
	SG_ B_LO_REGERR_ISO : 9|1@1+ (1,0) [0|1] "" DEBUG
	SG_ B_LO_UVLOD : 10|1@1+ (1,0) [0|1] "" DEBUG
	SG_ B_LO_OVLOD : 11|1@1+ (1,0) [0|1] "" DEBUG
	SG_ B_LO_REGERR_LV : 12|1@1+ (1,0) [0|1] "" DEBUG
	SG_ B_LO_SPI_ERR : 13|1@1+ (1,0) [0|1] "" DEBUG
	SG_ B_LO_DEADTIME_ERR : 14|1@1+ (1,0) [0|1] "" DEBUG
	SG_ B_HI_THERM_WARN : 15|1@1+ (1,0) [0|1] "" DEBUG
	SG_ B_HI_THERM_SHDN : 16|1@1+ (1,0) [0|1] "" DEBUG
	SG_ B_HI_UVLOL : 17|1@1+ (1,0) [0|1] "" DEBUG
	SG_ B_HI_UVLOH : 18|1@1+ (1,0) [0|1] "" DEBUG
	SG_ B_HI_SENSE : 19|1@1+ (1,0) [0|1] "" DEBUG
	SG_ B_HI_DESAT : 20|1@1+ (1,0) [0|1] "" DEBUG
	SG_ B_HI_OVLOL : 21|1@1+ (1,0) [0|1] "" DEBUG
	SG_ B_HI_OVLOH : 22|1@1+ (1,0) [0|1] "" DEBUG
	SG_ B_HI_ASC : 23|1@1+ (1,0) [0|1] "" DEBUG
	SG_ B_HI_REGERR_ISO : 24|1@1+ (1,0) [0|1] "" DEBUG
	SG_ B_HI_UVLOD : 25|1@1+ (1,0) [0|1] "" DEBUG
	SG_ B_HI_OVLOD : 26|1@1+ (1,0) [0|1] "" DEBUG
	SG_ B_HI_REGERR_LV : 27|1@1+ (1,0) [0|1] "" DEBUG
	SG_ B_HI_SPI_ERR : 28|1@1+ (1,0) [0|1] "" DEBUG
	SG_ B_HI_DEADTIME_ERR : 29|1@1+ (1,0) [0|1] "" DEBUG

BO_ 625 INV_PHC_STGAP_FAULTS : 4 INV
	SG_ C_LO_THERM_WARN : 0|1@1+ (1,0) [0|1] "" DEBUG
	SG_ C_LO_THERM_SHDN : 1|1@1+ (1,0) [0|1] "" DEBUG
	SG_ C_LO_UVLOL : 2|1@1+ (1,0) [0|1] "" DEBUG
	SG_ C_LO_UVLOH : 3|1@1+ (1,0) [0|1] "" DEBUG
	SG_ C_LO_SENSE : 4|1@1+ (1,0) [0|1] "" DEBUG
	SG_ C_LO_DESAT : 5|1@1+ (1,0) [0|1] "" DEBUG
	SG_ C_LO_OVLOL : 6|1@1+ (1,0) [0|1] "" DEBUG
	SG_ C_LO_OVLOH : 7|1@1+ (1,0) [0|1] "" DEBUG
	SG_ C_LO_ASC : 8|1@1+ (1,0) [0|1] "" DEBUG
	SG_ C_LO_REGERR_ISO : 9|1@1+ (1,0) [0|1] "" DEBUG
	SG_ C_LO_UVLOD : 10|1@1+ (1,0) [0|1] "" DEBUG
	SG_ C_LO_OVLOD : 11|1@1+ (1,0) [0|1] "" DEBUG
	SG_ C_LO_REGERR_LV : 12|1@1+ (1,0) [0|1] "" DEBUG
	SG_ C_LO_SPI_ERR : 13|1@1+ (1,0) [0|1] "" DEBUG
	SG_ C_LO_DEADTIME_ERR : 14|1@1+ (1,0) [0|1] "" DEBUG
	SG_ C_HI_THERM_WARN : 15|1@1+ (1,0) [0|1] "" DEBUG
	SG_ C_HI_THERM_SHDN : 16|1@1+ (1,0) [0|1] "" DEBUG
	SG_ C_HI_UVLOL : 17|1@1+ (1,0) [0|1] "" DEBUG
	SG_ C_HI_UVLOH : 18|1@1+ (1,0) [0|1] "" DEBUG
	SG_ C_HI_SENSE : 19|1@1+ (1,0) [0|1] "" DEBUG
	SG_ C_HI_DESAT : 20|1@1+ (1,0) [0|1] "" DEBUG
	SG_ C_HI_OVLOL : 21|1@1+ (1,0) [0|1] "" DEBUG
	SG_ C_HI_OVLOH : 22|1@1+ (1,0) [0|1] "" DEBUG
	SG_ C_HI_ASC : 23|1@1+ (1,0) [0|1] "" DEBUG
	SG_ C_HI_REGERR_ISO : 24|1@1+ (1,0) [0|1] "" DEBUG
	SG_ C_HI_UVLOD : 25|1@1+ (1,0) [0|1] "" DEBUG
	SG_ C_HI_OVLOD : 26|1@1+ (1,0) [0|1] "" DEBUG
	SG_ C_HI_REGERR_LV : 27|1@1+ (1,0) [0|1] "" DEBUG
	SG_ C_HI_SPI_ERR : 28|1@1+ (1,0) [0|1] "" DEBUG
	SG_ C_HI_DEADTIME_ERR : 29|1@1+ (1,0) [0|1] "" DEBUG

BO_ 626 INV_MOTOR_SHUTDOWN_ERROR_LOG : 4 INV
	SG_ PHA_HI_DIAG_LOG : 0|1@1+ (1,0) [0|1] "" DEBUG
	SG_ PHA_LO_DIAG_LOG : 1|1@1+ (1,0) [0|1] "" DEBUG
	SG_ PHB_HI_DIAG_LOG : 2|1@1+ (1,0) [0|1] "" DEBUG
	SG_ PHB_LO_DIAG_LOG : 3|1@1+ (1,0) [0|1] "" DEBUG
	SG_ PHC_HI_DIAG_LOG : 4|1@1+ (1,0) [0|1] "" DEBUG
	SG_ PHC_LO_DIAG_LOG : 5|1@1+ (1,0) [0|1] "" DEBUG
	SG_ PHA_OC_ALARM_LOG : 6|1@1+ (1,0) [0|1] "" DEBUG
	SG_ PHB_OC_ALARM_LOG : 7|1@1+ (1,0) [0|1] "" DEBUG
	SG_ PHC_OC_ALARM_LOG : 8|1@1+ (1,0) [0|1] "" DEBUG
	SG_ PWRSTG_OT_ALARM_LOG : 9|1@1+ (1,0) [0|1] "" DEBUG
	SG_ MOTOR_OT_ALARM_LOG : 10|1@1+ (1,0) [0|1] "" DEBUG
	SG_ STGAP_STATUS_FAULT_LOG : 11|1@1+ (1,0) [0|1] "" DEBUG
	SG_ STGAP_SHORT_TEST_LOG : 12|1@1+ (1,0) [0|1] "" DEBUG
	SG_ ROTOR_NO_RESPONSE_LOG : 13|1@1+ (1,0) [0|1] "" DEBUG
	SG_ ROTOR_CRC_CHECK_LOG : 14|1@1+ (1,0) [0|1] "" DEBUG
	SG_ CUR_SNS_OFFSET_LOG : 15|1@1+ (1,0) [0|1] "" DEBUG
	SG_ DAC_OC_THRESHOLD_LOG : 16|1@1+ (1,0) [0|1] "" DEBUG
	SG_ LL_PERIPH_FAULT_LOG : 17|1@1+ (1,0) [0|1] "" DEBUG
	SG_ MC_TORQUE_REQUEST_IMPLAUSIBLE_LOG : 18|1@1+ (1,0) [0|1] "" DEBUG
	SG_ MC_BUS_VOLTAGE_FAULT_LOG : 19|1@1+ (1,0) [0|1] "" DEBUG
	SG_ MC_ROTOR_POSITION_IMPLAUSIBLE_LOG : 20|1@1+ (1,0) [0|1] "" DEBUG
	SG_ MC_PHC_CUR_CALC_IMPLAUSIBLE_LOG : 21|1@1+ (1,0) [0|1] "" DEBUG
	SG_ MC_FUND_FREQ_REQ_IMPLAUSIBLE_LOG : 22|1@1+ (1,0) [0|1] "" DEBUG
	SG_ MC_ID_CONTROLLER_STABILITY_LOG : 23|1@1+ (1,0) [0|1] "" DEBUG
	SG_ MC_IQ_CONTROLLER_STABILITY_LOG : 24|1@1+ (1,0) [0|1] "" DEBUG
	SG_ MC_SPEED_CONTROLLER_STABILITY_LOG : 25|1@1+ (1,0) [0|1] "" DEBUG

BO_ 627 INV_MOTOR_SHUTDOWN_ERRORS : 4 INV
	SG_ PHA_HI_DIAG : 0|1@1+ (1,0) [0|1] "" DEBUG
	SG_ PHA_LO_DIAG : 1|1@1+ (1,0) [0|1] "" DEBUG
	SG_ PHB_HI_DIAG : 2|1@1+ (1,0) [0|1] "" DEBUG
	SG_ PHB_LO_DIAG : 3|1@1+ (1,0) [0|1] "" DEBUG
	SG_ PHC_HI_DIAG : 4|1@1+ (1,0) [0|1] "" DEBUG
	SG_ PHC_LO_DIAG : 5|1@1+ (1,0) [0|1] "" DEBUG
	SG_ PHA_OC_ALARM : 6|1@1+ (1,0) [0|1] "" DEBUG
	SG_ PHB_OC_ALARM : 7|1@1+ (1,0) [0|1] "" DEBUG
	SG_ PHC_OC_ALARM : 8|1@1+ (1,0) [0|1] "" DEBUG
	SG_ PWRSTG_OT_ALARM : 9|1@1+ (1,0) [0|1] "" DEBUG
	SG_ MOTOR_OT_ALARM : 10|1@1+ (1,0) [0|1] "" DEBUG
	SG_ STGAP_STATUS_FAULT : 11|1@1+ (1,0) [0|1] "" DEBUG
	SG_ STGAP_SHORT_TEST : 12|1@1+ (1,0) [0|1] "" DEBUG
	SG_ ROTOR_NO_RESPONSE : 13|1@1+ (1,0) [0|1] "" DEBUG
	SG_ ROTOR_CRC_CHECK : 14|1@1+ (1,0) [0|1] "" DEBUG
	SG_ CUR_SNS_OFFSET : 15|1@1+ (1,0) [0|1] "" DEBUG
	SG_ DAC_OC_THRESHOLD : 16|1@1+ (1,0) [0|1] "" DEBUG
	SG_ LL_PERIPH_FAULT : 17|1@1+ (1,0) [0|1] "" DEBUG
	SG_ MC_TORQUE_REQUEST_IMPLAUSIBLE : 18|1@1+ (1,0) [0|1] "" DEBUG
	SG_ MC_BUS_VOLTAGE_FAULT : 19|1@1+ (1,0) [0|1] "" DEBUG
	SG_ MC_ROTOR_POSITION_IMPLAUSIBLE : 20|1@1+ (1,0) [0|1] "" DEBUG
	SG_ MC_PHC_CUR_CALC_IMPLAUSIBLE : 21|1@1+ (1,0) [0|1] "" DEBUG
	SG_ MC_FUND_FREQ_REQ_IMPLAUSIBLE : 22|1@1+ (1,0) [0|1] "" DEBUG
	SG_ MC_ID_CONTROLLER_STABILITY : 23|1@1+ (1,0) [0|1] "" DEBUG
	SG_ MC_IQ_CONTROLLER_STABILITY : 24|1@1+ (1,0) [0|1] "" DEBUG
	SG_ MC_SPEED_CONTROLLER_STABILITY : 25|1@1+ (1,0) [0|1] "" DEBUG

BO_ 700 INV_ROTOR_SPEED_REQ : 2 DEBUG
	SG_ ROTOR_SPEED_REQ : 0|16@1- (1,0) [-32768|32767] "rpm" INV,DEBUG

BO_ 701 INV_MOD_INDEX_REQ : 2 DEBUG
	SG_ MOD_INDEX_REQ : 0|10@1+ (0.1,0) [0|100] "%" INV,DEBUG

BO_ 702 INV_PH_CUR_PEAK_REQ : 2 DEBUG
	SG_ PH_CUR_PEAK_REQ : 0|10@1+ (0.1,0) [0|80] "A" INV,DEBUG

BO_ 703 INV_FUND_FREQ_REQ : 2 DEBUG
	SG_ FUND_FREQ_REQ : 0|15@1+ (0.1,0) [0|2000] "Hz" INV,DEBUG

BO_ 704 INV_STATE_REQ : 1 DEBUG
	SG_ STATE_MACHINE_REQ : 0|2@1+ (1,0) [0|3] "" INV,DEBUG
	SG_ MODE_REQ : 2|2@1+ (1,0) [0|3] "" INV,DEBUG
	SG_ TORQUE_SPEED_MODE_REQ : 4|1@1+ (1,0) [0|1] "" INV,DEBUG
	SG_ NO_ROTOR_PRESENT : 5|1@1+ (1,0) [0|1] "" INV,DEBUG
	SG_ NO_BUS_VOLTAGE_PRESENT : 6|1@1+ (1,0) [0|1] "" INV,DEBUG

BA_DEF_  "BusType" STRING;
BA_DEF_ BO_  "GenMsgCycleTime" INT 0 65535;
BA_DEF_ SG_  "GenSigStartValue" INT 0 2147483647;

BA_DEF_DEF_  "BusType" "CAN";
BA_DEF_DEF_  "GenMsgCycleTime" 0;
BA_DEF_DEF_  "GenSigStartValue" 0;

BA_ "GenMsgCycleTime" BO_ 100 10;
BA_ "GenMsgCycleTime" BO_ 104 1000;
BA_ "GenMsgCycleTime" BO_ 105 1000;
BA_ "GenMsgCycleTime" BO_ 200 10;
BA_ "GenMsgCycleTime" BO_ 204 1000;
BA_ "GenMsgCycleTime" BO_ 206 10;
BA_ "GenMsgCycleTime" BO_ 207 10;
BA_ "GenMsgCycleTime" BO_ 301 10;
BA_ "GenMsgCycleTime" BO_ 401 10;
BA_ "GenMsgCycleTime" BO_ 500 10;
BA_ "GenMsgCycleTime" BO_ 503 10;
BA_ "GenMsgCycleTime" BO_ 505 10;
BA_ "GenMsgCycleTime" BO_ 506 1000;
BA_ "GenMsgCycleTime" BO_ 507 10;
BA_ "GenMsgCycleTime" BO_ 508 1000;
BA_ "GenMsgCycleTime" BO_ 600 100;
BA_ "GenMsgCycleTime" BO_ 601 1000;
BA_ "GenMsgCycleTime" BO_ 603 1000;
BA_ "GenMsgCycleTime" BO_ 605 100;
BA_ "GenMsgCycleTime" BO_ 606 100;
BA_ "GenMsgCycleTime" BO_ 607 100;
BA_ "GenMsgCycleTime" BO_ 608 100;
BA_ "GenMsgCycleTime" BO_ 609 100;
BA_ "GenMsgCycleTime" BO_ 610 100;
BA_ "GenMsgCycleTime" BO_ 611 100;
BA_ "GenMsgCycleTime" BO_ 612 100;
BA_ "GenMsgCycleTime" BO_ 613 100;
BA_ "GenMsgCycleTime" BO_ 614 1000;
BA_ "GenMsgCycleTime" BO_ 615 100;
BA_ "GenMsgCycleTime" BO_ 616 100;
BA_ "GenMsgCycleTime" BO_ 617 1000;
BA_ "GenMsgCycleTime" BO_ 618 100;
BA_ "GenMsgCycleTime" BO_ 619 100;
BA_ "GenMsgCycleTime" BO_ 620 1000;
BA_ "GenMsgCycleTime" BO_ 621 1000;
BA_ "GenMsgCycleTime" BO_ 622 1000;
BA_ "GenMsgCycleTime" BO_ 623 1000;
BA_ "GenMsgCycleTime" BO_ 624 1000;
BA_ "GenMsgCycleTime" BO_ 625 1000;
BA_ "GenMsgCycleTime" BO_ 626 1000;
BA_ "GenMsgCycleTime" BO_ 627 1000;
BA_ "GenMsgCycleTime" BO_ 700 100;
BA_ "GenMsgCycleTime" BO_ 701 100;
BA_ "GenMsgCycleTime" BO_ 702 100;
BA_ "GenMsgCycleTime" BO_ 703 100;
BA_ "GenMsgCycleTime" BO_ 704 100;

SIG_VALTYPE_ 206 FR_TORQUE_REQUEST : 1;
SIG_VALTYPE_ 206 FL_TORQUE_REQUEST : 1;
SIG_VALTYPE_ 207 RR_TORQUE_REQUEST : 1;
SIG_VALTYPE_ 207 RL_TORQUE_REQUEST : 1;

VAL_ 103 TASK_NAME 0 "TASK_1HZ" 1 "TASK_10HZ" 2 "TASK_100HZ" 3 "TASK_1KHZ" 4 "TASK_CANRX" 5 "TASK_CANTX";
VAL_ 104 SEGMENT_0_VOLTAGE_OUT_OF_RANGE 0 "OK" 1 "UNDERFLOW" 2 "OVERFLOW";
VAL_ 104 SEGMENT_1_VOLTAGE_OUT_OF_RANGE 0 "OK" 1 "UNDERFLOW" 2 "OVERFLOW";
VAL_ 104 SEGMENT_2_VOLTAGE_OUT_OF_RANGE 0 "OK" 1 "UNDERFLOW" 2 "OVERFLOW";
VAL_ 104 SEGMENT_3_VOLTAGE_OUT_OF_RANGE 0 "OK" 1 "UNDERFLOW" 2 "OVERFLOW";
VAL_ 104 SEGMENT_4_VOLTAGE_OUT_OF_RANGE 0 "OK" 1 "UNDERFLOW" 2 "OVERFLOW";
VAL_ 104 SEGMENT_5_VOLTAGE_OUT_OF_RANGE 0 "OK" 1 "UNDERFLOW" 2 "OVERFLOW";
VAL_ 104 PACK_VOLTAGE_OUT_OF_RANGE 0 "OK" 1 "UNDERFLOW" 2 "OVERFLOW";
VAL_ 104 AVERAGE_CELL_VOLTAGE_OUT_OF_RANGE 0 "OK" 1 "UNDERFLOW" 2 "OVERFLOW";
VAL_ 104 CELL_MONITOR_0_DIE_TEMP_OUT_OF_RANGE 0 "OK" 1 "UNDERFLOW" 2 "OVERFLOW";
VAL_ 104 CELL_MONITOR_1_DIE_TEMP_OUT_OF_RANGE 0 "OK" 1 "UNDERFLOW" 2 "OVERFLOW";
VAL_ 104 CELL_MONITOR_2_DIE_TEMP_OUT_OF_RANGE 0 "OK" 1 "UNDERFLOW" 2 "OVERFLOW";
VAL_ 104 CELL_MONITOR_3_DIE_TEMP_OUT_OF_RANGE 0 "OK" 1 "UNDERFLOW" 2 "OVERFLOW";
VAL_ 104 CELL_MONITOR_4_DIE_TEMP_OUT_OF_RANGE 0 "OK" 1 "UNDERFLOW" 2 "OVERFLOW";
VAL_ 104 CELL_MONITOR_5_DIE_TEMP_OUT_OF_RANGE 0 "OK" 1 "UNDERFLOW" 2 "OVERFLOW";
VAL_ 104 ITMP_CHARGER_HAS_OVERFLOW 0 "False" 1 "True";
VAL_ 105 CONDITION 0 "IMD_SHORT_CIRCUIT" 1 "IMD_NORMAL" 2 "IMD_UNDERVOLTAGE_DETECTED" 3 "IMD_SST" 4 "IMD_DEVICE_ERROR" 5 "IMD_EARTH_FAULT" 5 "IMD_INVALID";
VAL_ 105 OK_HS 0 "OK" 1 "FAULT";
VAL_ 107 STATE 0 "INIT" 1 "AIR_OPEN" 2 "PRE_CHARGE" 3 "CHARGE" 4 "DRIVE" 5 "FAULT";
VAL_ 109 CHARGER_DISCONNECTED_IN_CHARGE_STATE 0 "False" 1 "True";
VAL_ 109 MIN_CELL_VOLTAGE_OUT_OF_RANGE 0 "OK" 1 "UNDERFLOW" 2 "OVERFLOW";
VAL_ 109 MAX_CELL_VOLTAGE_OUT_OF_RANGE 0 "OK" 1 "UNDERFLOW" 2 "OVERFLOW";
VAL_ 112 AIR_POSITIVE 0 "OPEN" 1 "CLOSED";
VAL_ 112 AIR_NEGATIVE 0 "OPEN" 1 "CLOSED";
VAL_ 203 TASK_NAME 0 "TASK_1HZ" 1 "TASK_10HZ" 2 "TASK_100HZ" 3 "TASK_1KHZ" 4 "TASK_CANRX" 5 "TASK_CANTX";
VAL_ 204 ACCELERATION_X_OUT_OF_RANGE 0 "OK" 1 "UNDERFLOW" 2 "OVERFLOW";
VAL_ 204 ACCELERATION_Y_OUT_OF_RANGE 0 "OK" 1 "UNDERFLOW" 2 "OVERFLOW";
VAL_ 204 ACCELERATION_Z_OUT_OF_RANGE 0 "OK" 1 "UNDERFLOW" 2 "OVERFLOW";
VAL_ 205 STATE 0 "INIT" 1 "DRIVE" 2 "FAULT";
VAL_ 300 PAPPS_OUT_OF_RANGE 0 "OK" 1 "UNDERFLOW" 2 "OVERFLOW";
VAL_ 300 SAPPS_OUT_OF_RANGE 0 "OK" 1 "UNDERFLOW" 2 "OVERFLOW";
VAL_ 300 LEFT_WHEEL_SPEED_OUT_OF_RANGE 0 "OK" 1 "UNDERFLOW" 2 "OVERFLOW";
VAL_ 300 RIGHT_WHEEL_SPEED_OUT_OF_RANGE 0 "OK" 1 "UNDERFLOW" 2 "OVERFLOW";
VAL_ 300 PRIMARY_FLOW_RATE_OUT_OF_RANGE 0 "OK" 1 "UNDERFLOW" 2 "OVERFLOW";
VAL_ 300 SECONDARY_FLOW_RATE_OUT_OF_RANGE 0 "OK" 1 "UNDERFLOW" 2 "OVERFLOW";
VAL_ 300 STEERING_ANGLE_OUT_OF_RANGE 0 "OK" 1 "UNDERFLOW" 2 "OVERFLOW";
VAL_ 300 BRAKE_PRESSURE_OUT_OF_RANGE 0 "OK" 1 "UNDERFLOW" 2 "OVERFLOW";
VAL_ 304 TASK_NAME 0 "TASK_1HZ" 1 "TASK_10HZ" 2 "TASK_100HZ" 3 "TASK_1KHZ" 4 "TASK_CANRX" 5 "TASK_CANTX";
VAL_ 305 STATE 0 "AIR_OPEN" 1 "AIR_CLOSED";
VAL_ 308 BRAKE_IS_ACTUATED 0 "False" 1 "True";
VAL_ 308 PRESSURE_SENSOR_IS_OPEN_OR_SHORT_CIRCUIT 0 "False" 1 "True";
VAL_ 314 APPS_HAS_DISAGREEMENT 0 "False" 1 "True";
VAL_ 314 PAPPS_ALARM_IS_ACTIVE 0 "False" 1 "True";
VAL_ 314 SAPPS_ALARM_IS_ACTIVE 0 "False" 1 "True";
VAL_ 314 PLAUSIBILITY_CHECK_HAS_FAILED 0 "False" 1 "True";
VAL_ 314 PRIMARY_FLOW_RATE_HAS_UNDERFLOW 0 "False" 1 "True";
VAL_ 314 SECONDARY_FLOW_RATE_HAS_UNDERFLOW 0 "False" 1 "True";
VAL_ 400 VBAT_VOLTAGE_OUT_OF_RANGE 0 "OK" 1 "UNDERFLOW" 2 "OVERFLOW";
VAL_ 400 _24V_AUX_VOLTAGE_OUT_OF_RANGE 0 "OK" 1 "UNDERFLOW" 2 "OVERFLOW";
VAL_ 400 _24V_ACC_VOLTAGE_OUT_OF_RANGE 0 "OK" 1 "UNDERFLOW" 2 "OVERFLOW";
VAL_ 400 AUX1_CURRENT_OUT_OF_RANGE 0 "OK" 1 "UNDERFLOW" 2 "OVERFLOW";
VAL_ 400 AUX2_CURRENT_OUT_OF_RANGE 0 "OK" 1 "UNDERFLOW" 2 "OVERFLOW";
VAL_ 400 LEFT_INVERTER_CURRENT_OUT_OF_RANGE 0 "OK" 1 "UNDERFLOW" 2 "OVERFLOW";
VAL_ 400 RIGHT_INVERTER_CURRENT_OUT_OF_RANGE 0 "OK" 1 "UNDERFLOW" 2 "OVERFLOW";
VAL_ 400 ENERGY_METER_CURRENT_OUT_OF_RANGE 0 "OK" 1 "UNDERFLOW" 2 "OVERFLOW";
VAL_ 400 CAN_CURRENT_OUT_OF_RANGE 0 "OK" 1 "UNDERFLOW" 2 "OVERFLOW";
VAL_ 400 AIR_SHUTDOWN_CURRENT_OUT_OF_RANGE 0 "OK" 1 "UNDERFLOW" 2 "OVERFLOW";
VAL_ 412 TASK_NAME 0 "TASK_1HZ" 1 "TASK_10HZ" 2 "TASK_100HZ" 3 "TASK_1KHZ" 4 "TASK_CANRX" 5 "TASK_CANTX";
VAL_ 413 STATE 0 "INIT" 1 "AIR_OPEN" 2 "AIR_CLOSED";
VAL_ 503 STATE 0 "DRIVE";
VAL_ 504 TASK_NAME 0 "TASK_1HZ" 1 "TASK_10HZ" 2 "TASK_100HZ" 3 "TASK_1KHZ" 4 "TASK_CANRX" 5 "TASK_CANTX";
VAL_ 506 DRIVE_MODE 0 "DRIVE_MODE_1" 1 "DRIVE_MODE_2" 2 "DRIVE_MODE_3" 3 "DRIVE_MODE_4" 4 "DRIVE_MODE_5" 5 "DRIVE_MODE_INVALID";
VAL_ 507 START_SWITCH 0 "OFF" 1 "ON";
VAL_ 507 TRACTION_CONTROL_SWITCH 0 "OFF" 1 "ON";
VAL_ 507 TORQUE_VECTORING_SWITCH 0 "OFF" 1 "ON";
VAL_ 602 TASK_NAME 0 "TASK_1HZ" 1 "TASK_10HZ" 2 "TASK_100HZ" 3 "TASK_1KHZ" 4 "TASK_CANRX" 5 "TASK_CANTX";
VAL_ 619 MODE 0 "UNDEFINED" 1 "GEN_SINE_M" 2 "GEN_SINE_I" 3 "MOTOR_CONTROL";
VAL_ 619 MODE_COMMAND 0 "UNDEFINED" 1 "GEN_SINE_M" 2 "GEN_SINE_I" 3 "MOTOR_CONTROL";
VAL_ 619 STATE 0 "INIT" 1 "STANDBY" 2 "DRIVE" 3 "FAULT";
VAL_ 619 STATE_COMMAND 0 "INIT" 1 "STANDBY" 2 "DRIVE" 3 "FAULT";
VAL_ 626 MC_ID_CONTROLLER_STABILITY_LOG 0 "STABLE" 1 "UNSTABLE";
VAL_ 626 MC_IQ_CONTROLLER_STABILITY_LOG 0 "STABLE" 1 "UNSTABLE";
VAL_ 626 MC_SPEED_CONTROLLER_STABILITY_LOG 0 "STABLE" 1 "UNSTABLE";
VAL_ 627 MC_ID_CONTROLLER_STABILITY 0 "STABLE" 1 "UNSTABLE";
VAL_ 627 MC_IQ_CONTROLLER_STABILITY 0 "STABLE" 1 "UNSTABLE";
VAL_ 627 MC_SPEED_CONTROLLER_STABILITY 0 "STABLE" 1 "UNSTABLE";
VAL_ 704 STATE_MACHINE_REQ 0 "INIT" 1 "STANDBY" 2 "DRIVE" 3 "FAULT";
VAL_ 704 MODE_REQ 0 "UNDEFINED" 1 "GEN_SINE_M" 2 "GEN_SINE_I" 3 "MOTOR_CONTROL";
VAL_ 704 TORQUE_SPEED_MODE_REQ 0 "TORQUE_MODE" 1 "SPEED_MODE";
VAL_ 704 NO_ROTOR_PRESENT 0 "ROTOR_PRESENT" 1 "NO_ROTOR_PRESENT";
VAL_ 704 NO_BUS_VOLTAGE_PRESENT 0 "BUS_VOLTAGE_PRESENT" 1 "NO_BUS_VOLTAGE_PRESENT";
